# DEBUGSS_WRAP_PWRAP_CFG_0_000700002300h register map
Vendor: Texas Instruments
Peripheral module from a debugger description file (folder AM275x).
Registers are 32-bit, read-only, reset values left out (the file's numbers can be read two ways) unless marked. A register's access mark holds for its fields unless they carry their own. Offsets are as the file gives them; lines under a group give offsets from that group; [hi:lo] are bit positions; {n}, {i} and the like mark numbered series; 'fields as' and 'values as' point back to an identical list; <NAME> marks a mode.

## pwrap_cfg_0
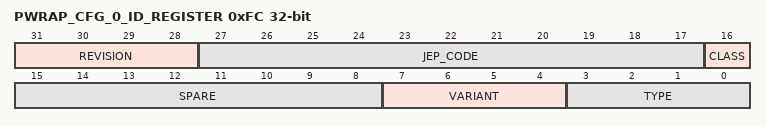
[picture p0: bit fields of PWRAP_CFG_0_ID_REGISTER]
0xFC PWRAP_CFG_0_ID_REGISTER — Reading this register returns the ID information for this AP.
  [31:28] REVISION — Device Revision [0]
  [27:17] JEP_CODE — Device JEP Code [0x017]
  [16] CLASS — Device Class[1] [a memory access port]
  [15:8] SPARE — Spare, returns 0
  [7:4] VARIANT — Device Variant [0]
  [3:0] TYPE — Device Type: 0=JTAG, 1=AHB, 2=APB [2]
